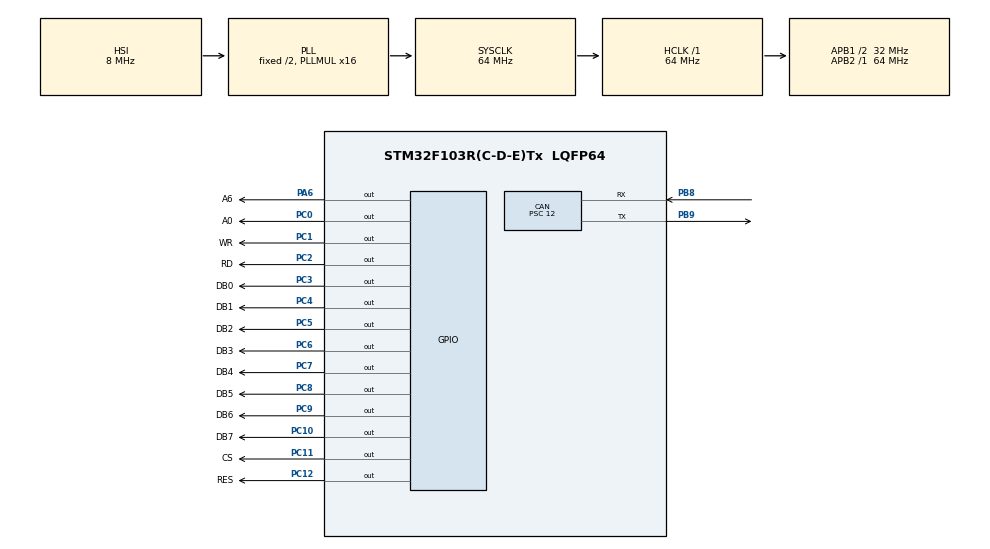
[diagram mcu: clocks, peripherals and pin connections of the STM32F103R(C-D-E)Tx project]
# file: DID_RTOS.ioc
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CAN.BS1=CAN_BS1_13TQ
CAN.BS2=CAN_BS2_2TQ
CAN.CalculateBaudRate=166666
CAN.CalculateTimeBit=6000.00
CAN.CalculateTimeQuantum=375.0
CAN.Prescaler=12
FREERTOS.Tasks01=messageReceive,24,128,messageReceiveTask,Default,NULL,Dynamic,NULL,NULL;updateDisplay,8,128,updateDisplayTask,Default,NULL,Dynamic,NULL,NULL
FREERTOS.configUSE_NEWLIB_REENTRANT=1
Mcu.Family=STM32F1
Mcu.Name=STM32F103R(C-D-E)Tx
Mcu.Package=LQFP64
NVIC.PriorityGroup=NVIC_PRIORITYGROUP_4
PA13.Mode=Serial_Wire
PA13.Signal=SYS_JTMS-SWDIO
PA14.Mode=Serial_Wire
PA14.Signal=SYS_JTCK-SWCLK
PA6.GPIO_Label=A6
PA6.GPIO_PuPd=GPIO_PULLDOWN
PA6.Signal=GPIO_Output
PB8.Mode=CAN_Activate
PB8.Signal=CAN_RX
PB9.Mode=CAN_Activate
PB9.Signal=CAN_TX
PC0.GPIO_Label=A0
PC0.Signal=GPIO_Output
PC1.GPIO_Label=WR
PC1.Signal=GPIO_Output
PC10.GPIO_Label=DB7
PC10.Signal=GPIO_Output
PC11.GPIO_Label=CS
PC11.Signal=GPIO_Output
PC12.GPIO_Label=RES
PC12.Signal=GPIO_Output
PC2.GPIO_Label=RD
PC2.Signal=GPIO_Output
PC3.GPIO_Label=DB0
PC3.Signal=GPIO_Output
PC4.GPIO_Label=DB1
PC4.Signal=GPIO_Output
PC5.GPIO_Label=DB2
PC5.Signal=GPIO_Output
PC6.GPIO_Label=DB3
PC6.Signal=GPIO_Output
PC7.GPIO_Label=DB4
PC7.Signal=GPIO_Output
PC8.GPIO_Label=DB5
PC8.Signal=GPIO_Output
PC9.GPIO_Label=DB6
PC9.Signal=GPIO_Output
ProjectManager.HeapSize=0x200
ProjectManager.StackSize=0x400
ProjectManager.TargetToolchain=STM32CubeIDE
RCC.AHBFreq_Value=64000000
RCC.APB1CLKDivider=RCC_HCLK_DIV2
RCC.APB1Freq_Value=32000000
RCC.APB1TimFreq_Value=64000000
RCC.APB2Freq_Value=64000000
RCC.APB2TimFreq_Value=64000000
RCC.HCLKFreq_Value=64000000
RCC.PLLMUL=RCC_PLL_MUL16
RCC.SYSCLKFreq_VALUE=64000000
RCC.SYSCLKSource=RCC_SYSCLKSOURCE_PLLCLK
RCC.USBFreq_Value=64000000
VP_FREERTOS_VS_CMSIS_V2.Mode=CMSIS_V2
board=custom

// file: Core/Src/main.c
/* USER CODE BEGIN Header */
/**
  ******************************************************************************
  * @file           : main.c
  * @brief          : Main program body
  ******************************************************************************
  * @attention
  *
  * <h2><center>&copy; Copyright (c) 2022 STMicroelectronics.
  * All rights reserved.</center></h2>
  *
  * This software component is licensed by ST under BSD 3-Clause license,
  * the "License"; You may not use this file except in compliance with the
  * License. You may obtain a copy of the License at:
  *                        opensource.org/licenses/BSD-3-Clause
  *
  ******************************************************************************
  */
/* USER CODE END Header */
#include "main.h"
#include "cmsis_os.h"
#include "can.h"
#include "gpio.h"

/* USER CODE BEGIN Includes */
#include "LCD.h"

/* USER CODE END Includes */

/* USER CODE BEGIN PV */

// CAN filtering
CAN_FilterTypeDef CAN_filter0;
CAN_FilterTypeDef CAN_filter1;

// CAN receiving
CAN_RxHeaderTypeDef CAN_rx_header;

/* USER CODE END PV */

void SystemClock_Config(void);
void MX_FREERTOS_Init(void);

int main(void)
{

  /* MCU Configuration--------------------------------------------------------*/

  /* Reset of all peripherals, Initializes the Flash interface and the Systick. */
  HAL_Init();

  /* Configure the system clock */
  SystemClock_Config();

  /* Initialize all configured peripherals */
  MX_GPIO_Init();
  MX_CAN_Init();
  /* USER CODE BEGIN 2 */

  // CAN Initialization
  CanFilterSetup();
  HAL_CAN_Start(&hcan);

  // Display startup screen
  ScreenSetup();
  ClearScreen();
  DisplayScreen();

  /* USER CODE END 2 */

  /* Init scheduler */
  osKernelInitialize();  /* Call init function for freertos objects (in freertos.c) */
  MX_FREERTOS_Init();
  /* Start scheduler */
  osKernelStart();

  /* We should never get here as control is now taken by the scheduler */
  /* Infinite loop */
  while (1)
  {

  }
}

void SystemClock_Config(void)
{
  RCC_OscInitTypeDef RCC_OscInitStruct = {0};
  RCC_ClkInitTypeDef RCC_ClkInitStruct = {0};

  /** Initializes the RCC Oscillators according to the specified parameters
  * in the RCC_OscInitTypeDef structure.
  */
  RCC_OscInitStruct.OscillatorType = RCC_OSCILLATORTYPE_HSI;
  RCC_OscInitStruct.HSIState = RCC_HSI_ON;
  RCC_OscInitStruct.HSICalibrationValue = RCC_HSICALIBRATION_DEFAULT;
  RCC_OscInitStruct.PLL.PLLState = RCC_PLL_ON;
  RCC_OscInitStruct.PLL.PLLSource = RCC_PLLSOURCE_HSI_DIV2;
  RCC_OscInitStruct.PLL.PLLMUL = RCC_PLL_MUL16;
  if (HAL_RCC_OscConfig(&RCC_OscInitStruct) != HAL_OK)
  {
    Error_Handler();
  }
  /** Initializes the CPU, AHB and APB buses clocks
  */
  RCC_ClkInitStruct.ClockType = RCC_CLOCKTYPE_HCLK|RCC_CLOCKTYPE_SYSCLK
                              |RCC_CLOCKTYPE_PCLK1|RCC_CLOCKTYPE_PCLK2;
  RCC_ClkInitStruct.SYSCLKSource = RCC_SYSCLKSOURCE_PLLCLK;
  RCC_ClkInitStruct.AHBCLKDivider = RCC_SYSCLK_DIV1;
  RCC_ClkInitStruct.APB1CLKDivider = RCC_HCLK_DIV2;
  RCC_ClkInitStruct.APB2CLKDivider = RCC_HCLK_DIV1;

  if (HAL_RCC_ClockConfig(&RCC_ClkInitStruct, FLASH_LATENCY_2) != HAL_OK)
  {
    Error_Handler();
  }
}

void Error_Handler(void)
{
  __disable_irq();
  while (1)
  {
  }
}

/************************ (C) COPYRIGHT STMicroelectronics *****END OF FILE****/

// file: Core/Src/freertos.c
/* USER CODE BEGIN Header */
/**
  ******************************************************************************
  * File Name          : freertos.c
  * Description        : Code for freertos applications
  ******************************************************************************
  * @attention
  *
  * <h2><center>&copy; Copyright (c) 2022 STMicroelectronics.
  * All rights reserved.</center></h2>
  *
  * This software component is licensed by ST under Ultimate Liberty license
  * SLA0044, the "License"; You may not use this file except in compliance with
  * the License. You may obtain a copy of the License at:
  *                             www.st.com/SLA0044
  *
  ******************************************************************************
  */
/* USER CODE END Header */

#include "FreeRTOS.h"
#include "task.h"
#include "main.h"
#include "cmsis_os.h"

/* USER CODE BEGIN Includes */
#include "can.h"

/* USER CODE END Includes */

/* Definitions for messageReceive */
osThreadId_t messageReceiveHandle;
const osThreadAttr_t messageReceive_attributes = {
  .name = "messageReceive",
  .stack_size = 128 * 4,
  .priority = (osPriority_t) osPriorityNormal,
};
/* Definitions for updateDisplay */
osThreadId_t updateDisplayHandle;
const osThreadAttr_t updateDisplay_attributes = {
  .name = "updateDisplay",
  .stack_size = 128 * 4,
  .priority = (osPriority_t) osPriorityLow,
};

void messageReceiveTask(void *argument);
void updateDisplayTask(void *argument);

void MX_FREERTOS_Init(void); /* (MISRA C 2004 rule 8.1) */

void MX_FREERTOS_Init(void) {

  /* Create the thread(s) */
  /* creation of messageReceive */
  messageReceiveHandle = osThreadNew(messageReceiveTask, NULL, &messageReceive_attributes);

  /* creation of updateDisplay */
  updateDisplayHandle = osThreadNew(updateDisplayTask, NULL, &updateDisplay_attributes);

}

void messageReceiveTask(void *argument)
{
	uint8_t msg_data[8];

	while (1) {
		if (HAL_CAN_GetRxFifoFillLevel(&hcan, CAN_RX_FIFO0)) {
			// there are multiple CAN IDs being passed through the filter, check if the message is the SOC
			HAL_CAN_GetRxMessage(&hcan, CAN_RX_FIFO0, &CAN_rx_header, msg_data);
			if (CAN_rx_header.StdId == 0x626) {

				// if the battery SOC is out of range, assume it is at 100% as a safety measure
				if (msg_data[0] < 0 || msg_data[0] > 100) {

				} else {

				}

			}
		}

		osDelay(1);
	}
}

void updateDisplayTask(void *argument)
{
  for(;;)
  {
    osDelay(1);
  }
}

/************************ (C) COPYRIGHT STMicroelectronics *****END OF FILE****/
